# DMPAC0_PAR_DOF_CFG_VP_MEM_MMRRAM_VBUSP_MMR_RAM register map
Vendor: Texas Instruments
Peripheral module from a debugger description file (folder J7ES).
Registers are 32-bit, read-only, reset 0x0 unless marked. A register's access mark holds for its fields unless they carry their own. Offsets are as the file gives them; lines under a group give offsets from that group; [hi:lo] are bit positions; {n}, {i} and the like mark numbered series; 'fields as' and 'values as' point back to an identical list; <NAME> marks a mode.

## DMPAC0_PAR_DOF_CFG_VP_MEM_MMRRAM_VBUSP_MMR_RAM
0x00 DMPAC_DOF_PSE_MEM_RAM_Y — pse_mem_ram diagnostic read only port, vbusp will stall until RAM is available for read Offset = 000C0000h + (y * 4h); where y = 0h to 7FFh
  [31:0] DATA — Data read from RAM.RAM is wider than 32bit vbus. MMR reads are byte addresses into RAM where RAM Width is extended/zero padded to next pwr2.
{0x2000+0x2000*i} DMPAC_DOF_SRB_MEM{i}_RAM_Y (i=0..3) — srb_mem{i}_ram diagnostic read only port, vbusp will stall until RAM is available for read Offset = 000C{2000i+2000}h + (y * 4h); where y = 0h to 7FFh
  fields as DMPAC_DOF_PSE_MEM_RAM_Y
0xA000 DMPAC_DOF_SRB_MEM4_RAM_Y — srb_mem4_ram diagnostic read only port, vbusp will stall until RAM is available for read Offset = 000CA000h + (y * 4h); where y = 0h to 7FFh
  fields as DMPAC_DOF_PSE_MEM_RAM_Y
0xC000 DMPAC_DOF_SRB_MEM5_RAM_Y — srb_mem5_ram diagnostic read only port, vbusp will stall until RAM is available for read Offset = 000CC000h + (y * 4h); where y = 0h to 7FFh
  fields as DMPAC_DOF_PSE_MEM_RAM_Y
0xE000 DMPAC_DOF_SRB_MEM6_RAM_Y — srb_mem6_ram diagnostic read only port, vbusp will stall until RAM is available for read Offset = 000CE000h + (y * 4h); where y = 0h to 7FFh
  fields as DMPAC_DOF_PSE_MEM_RAM_Y
{0x2000+0x2000*i} DMPAC_DOF_SRB_MEM{i}_RAM_Y (i=7..11) — srb_mem{i}_ram diagnostic read only port, vbusp will stall until RAM is available for read Offset = 000D{2000i-14000:04}h + (y * 4h); where y = 0h to 7FFh
  fields as DMPAC_DOF_PSE_MEM_RAM_Y
0x1A000 DMPAC_DOF_SRB_MEM12_RAM_Y — srb_mem12_ram diagnostic read only port, vbusp will stall until RAM is available for read Offset = 000DA000h + (y * 4h); where y = 0h to 7FFh
  fields as DMPAC_DOF_PSE_MEM_RAM_Y
0x1C000 DMPAC_DOF_SRB_MEM13_RAM_Y — srb_mem13_ram diagnostic read only port, vbusp will stall until RAM is available for read Offset = 000DC000h + (y * 4h); where y = 0h to 7FFh
  fields as DMPAC_DOF_PSE_MEM_RAM_Y
0x1E000 DMPAC_DOF_SRB_MEM14_RAM_Y — srb_mem14_ram diagnostic read only port, vbusp will stall until RAM is available for read Offset = 000DE000h + (y * 4h); where y = 0h to 7FFh
  fields as DMPAC_DOF_PSE_MEM_RAM_Y
0x20000 DMPAC_DOF_SRB_MEM15_RAM_Y — srb_mem15_ram diagnostic read only port, vbusp will stall until RAM is available for read Offset = 000E0000h + (y * 4h); where y = 0h to 7FFh
  fields as DMPAC_DOF_PSE_MEM_RAM_Y
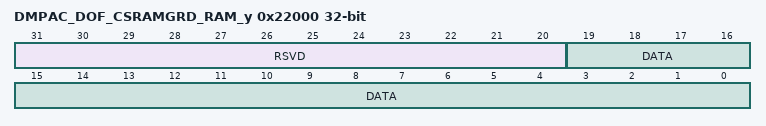
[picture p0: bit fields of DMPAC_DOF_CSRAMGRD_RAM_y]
0x22000 DMPAC_DOF_CSRAMGRD_RAM_y — csRamGrd_ram diagnostic read only port, vbusp will stall until RAM is available for read Offset = 000E2000h + (y * 4h); where y = 0h to 7FFh
  [31:20] RSVD — Always read as 0.Writes have no effect.
  [19:0] DATA — Data read from RAM
0x24000 DMPAC_DOF_CSRAMIIR_RAM_y — csRamIir_ram diagnostic read only port, vbusp will stall until RAM is available for read Offset = 000E4000h + (y * 4h); where y = 0h to FFFh
  fields as DMPAC_DOF_PSE_MEM_RAM_Y
0x28000 DMPAC_DOF_MFRAM0_RAM_y — mfRam0_ram diagnostic read only port, vbusp will stall until RAM is available for read Offset = 000E8000h + (y * 4h); where y = 0h to FFFh
  fields as DMPAC_DOF_PSE_MEM_RAM_Y
0x2C000 DMPAC_DOF_MFRAM1_RAM_y — mfRam1_ram diagnostic read only port, vbusp will stall until RAM is available for read Offset = 000EC000h + (y * 4h); where y = 0h to FFFh
  fields as DMPAC_DOF_PSE_MEM_RAM_Y
